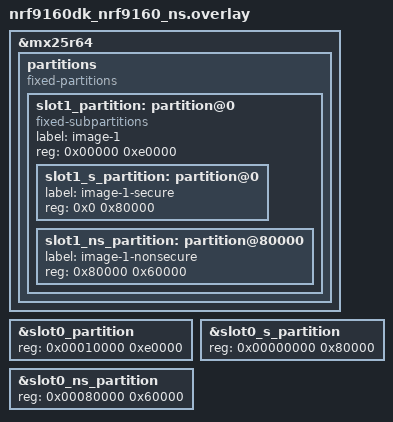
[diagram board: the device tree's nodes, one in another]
#include <samples/cellular/nrf91_no_bootloader_partitions.dtsi>
#include <samples/cellular/nrf91_sram_partitions.dtsi>

/delete-node/ &slot1_partition;

&mx25r64 {
    status = "okay";

    partitions {
        compatible = "fixed-partitions";
        #address-cells = <1>;
        #size-cells = <1>;

        slot1_partition: partition@0 {
            compatible = "fixed-subpartitions";
            label = "image-1";
            reg = <0x00000 0xe0000>;
            #address-cells = <1>;
            #size-cells = <1>;

            slot1_s_partition: partition@0 {
                label = "image-1-secure";
                reg = <0x0 0x80000>;
            };

            slot1_ns_partition: partition@80000 {
                label = "image-1-nonsecure";
                reg = <0x80000 0x60000>;
            };
        };
    };
};

&slot0_partition {
    reg = <0x00010000 0xe0000>;
    ranges = <0x0 0x10000 0xe0000>;
};

&slot0_s_partition {
    reg = <0x00000000 0x80000>;
};

&slot0_ns_partition {
    reg = <0x00080000 0x60000>;
};
